AUTOSAR XML (schema 4-0-3)
package /ComponentTypes
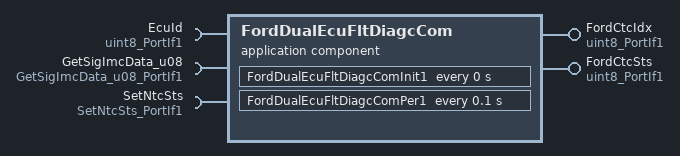
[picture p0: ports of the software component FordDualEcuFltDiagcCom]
  application sw component type FordDualEcuFltDiagcCom
    provide port FordCtcIdx: nonqueued-sender-com-spec{data-element=Val, init-value=0}, provided-interface=uint8_PortIf1
    provide port FordCtcSts: nonqueued-sender-com-spec{data-element=Val, init-value=0}, provided-interface=uint8_PortIf1
    require port EcuId: nonqueued-receiver-com-spec{data-element=Val, filter=data-filter-type=ALWAYS, init-value=0}, required-interface=uint8_PortIf1
    require port GetSigImcData_u08: client-com-spec=Oper, required-interface=GetSigImcData_u08_PortIf1
    require port SetNtcSts: client-com-spec=Oper, required-interface=SetNtcSts_PortIf1
    behavior FordDualEcuFltDiagcCom_InternalBehavior
      ar-typed-per-instance-memorys:
        data FordCTCLoopIdx: sw-calibration-access=READ-ONLY, type=uint8
      timing event FordDualEcuFltDiagcComInit1_InitEvent: start-on-event=FordDualEcuFltDiagcComInit1, period=0
      timing event TMT_FordDualEcuFltDiagcComPer1: start-on-event=FordDualEcuFltDiagcComPer1, period=0.1
      port-api-options:
        enable-take-address=false, indirect-api=false, port=EcuId
        enable-take-address=false, indirect-api=false, port=FordCtcIdx
        enable-take-address=false, indirect-api=false, port=FordCtcSts
        enable-take-address=false, indirect-api=false, port=GetSigImcData_u08
        enable-take-address=false, indirect-api=false, port=SetNtcSts
      runnable FordDualEcuFltDiagcComInit1
      runnable FordDualEcuFltDiagcComPer1
        data-receive-point-by-arguments:
          access REC_EcuId_Val: accessed-variable=EcuId.Val
        data-send-points:
          access SEND_FordCTCIdx_Val: accessed-variable=FordCtcIdx.Val
          access SEND_FordCTCSts_Val: accessed-variable=FordCtcSts.Val
        sync call SC_GetSigImcData_u08_Oper: operation=GetSigImcData_u08.Oper, timeout=0
        sync call SC_SetNtcSts_Oper: operation=SetNtcSts.Oper, timeout=0
  swc implementation FordDualEcuFltDiagcCom_Implementation: behavior=FordDualEcuFltDiagcCom_InternalBehavior
    code-descriptors:
      code Default: artifact-descriptors=autosar-engineering-object={short-label=Default, category=SWSRC}
